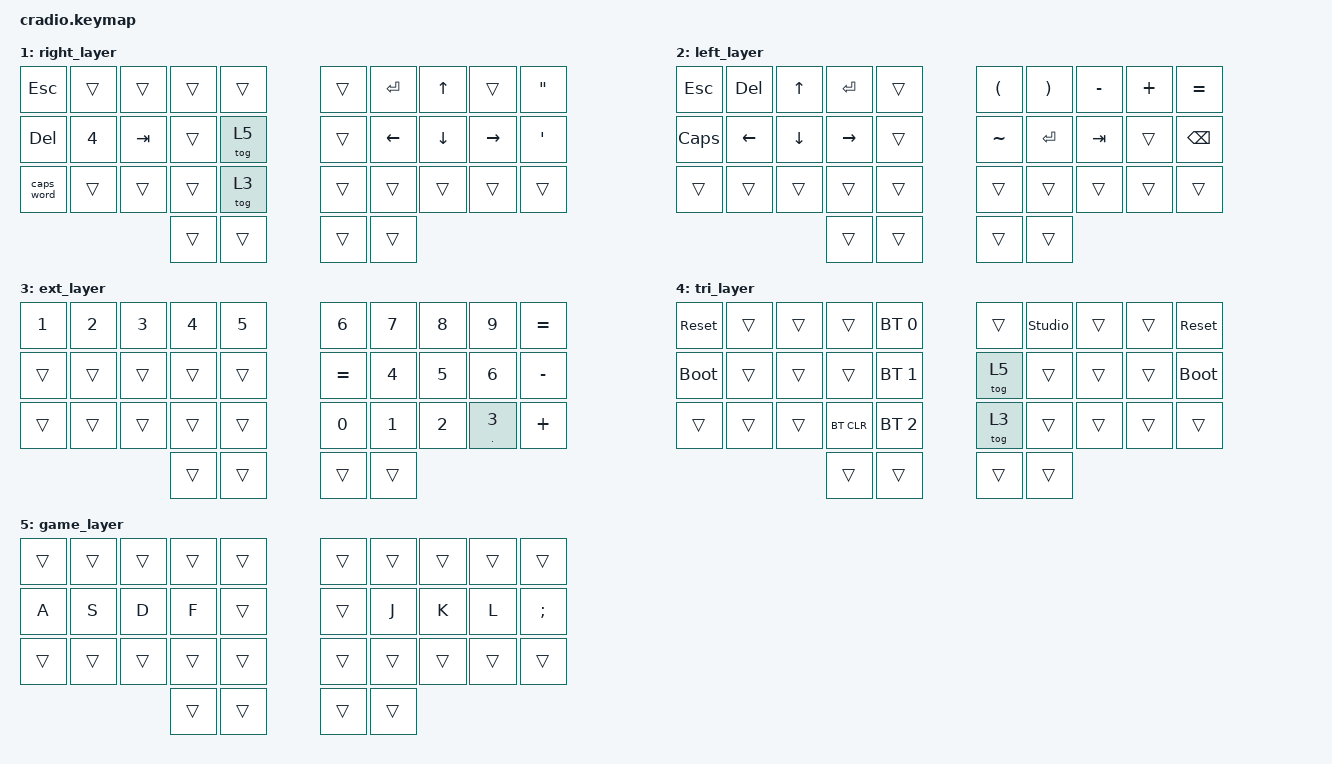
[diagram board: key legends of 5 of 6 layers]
// Copyright (c) 2022 The ZMK Contributors
// SPDX-License-Identifier: MIT

#include <behaviors.dtsi>
#include <dt-bindings/zmk/keys.h>
#include <dt-bindings/zmk/bt.h>

// Home row mods macro
#define HRML(k1,k2,k3,k4) &ht LSHFT k1  &ht LALT k2  &ht LCTRL k3  &ht LGUI k4
#define HRMR(k1,k2,k3,k4) &ht RGUI k1  &ht RCTRL k2  &ht RALT k3  &ht RSHFT k4

/ {
    behaviors {
        ht: hold_tap {
            compatible = "zmk,behavior-hold-tap";
            #binding-cells = <2>;
            flavor = "tap-preferred";
            tapping-term-ms = <220>;
            quick-tap-ms = <150>;
            require-prior-idle-ms = <100>;
            bindings = <&kp>, <&kp>;
        };

    };

    conditional_layers {
        compatible = "zmk,conditional-layers";
        tri_layer {
            if-layers = <1 2>;
            then-layer = <4>;
        };
    };

    keymap {
        compatible = "zmk,keymap";
        default_layer {
            bindings = <
        //╭──────────┬──────────┬──────────┬──────────┬──────────╮   ╭──────────┬──────────┬──────────┬──────────┬──────────╮
        //│  Q       │  W       │  E       │  R       │  T       │   │  Y       │  U       │  I       │  O       │  P       │
            &kp Q      &kp W      &kp E      &kp R      &kp T          &kp Y      &kp U      &kp I      &kp O      &kp P
        //├──────────┼──────────┼──────────┼──────────┼──────────┤   ├──────────┼──────────┼──────────┼──────────┼──────────┤
        //│  A       │  S       │  D       │  F       │  G       │   │  H       │  J       │  K       │  L       │ ; :      │
            HRML(A,        S,         D,         F)     &kp G          &kp H      HRMR(J,        K,         L,        SEMI)
        //├──────────┼──────────┼──────────┼──────────┼──────────┤   ├──────────┼──────────┼──────────┼──────────┼──────────┤
        //│  Z       │  X       │  C       │  V       │  B       │   │  N       │  M       │ , <      │ . >      │ / ?      │
            &kp Z      &kp X      &kp C      &kp V      &kp B          &kp N      &kp M      &kp COMMA  &kp DOT    &kp FSLH
        //╰──────────┴──────────┴──────────┼──────────┼──────────┤   ├──────────┼──────────┼──────────┴──────────┴──────────╯
                                           &lt 2 SPACE &lt 3 TAB       &lt 3 BSPC &lt 1 SPACE
        //                                 ╰──────────┴──────────╯   ╰──────────┴──────────╯
            >;
        };

        right_layer {
            bindings = <
        //╭──────────┬──────────┬──────────┬──────────┬──────────╮   ╭──────────┬──────────┬──────────┬──────────┬──────────╮
        //│   ESC    │          │          │          │          │   │          │    RET   │    UP    │          │     "    │
            &kp ESC    &trans     &trans     &trans     &trans         &trans     &kp RET    &kp UP     &trans     &kp DQT
        //├──────────┼──────────┼──────────┼──────────┼──────────┤   ├──────────┼──────────┼──────────┼──────────┼──────────┤
        //│ DELETE   │          │   TAB    │          │          │   │          │  LEFT    │   DOWN   │   RIGHT  │     '    │
            &kp DEL    &kp N4     &kp TAB     &trans     &tog 5        &trans     &kp LEFT   &kp DOWN   &kp RIGHT  &kp SQT
        //├──────────┼──────────┼──────────┼──────────┼──────────┤   ├──────────┼──────────┼──────────┼──────────┼──────────┤
        //│ CAPS     │          │          │          │          │   │          │          │          │          │          │
           &caps_word  &trans     &trans     &trans     &tog 3         &trans     &trans     &trans     &trans     &trans
        //╰──────────┴──────────┴──────────┼──────────┼──────────┤   ├──────────┼──────────┼──────────┴──────────┴──────────╯
                                             &trans     &trans         &trans     &trans
        //                                 ╰──────────┴──────────╯   ╰──────────┴──────────╯
            >;
        };

        left_layer {
            bindings = <
        //╭──────────┬──────────┬──────────┬──────────┬──────────╮   ╭──────────┬──────────┬──────────┬──────────┬──────────╮
        //│   ESC    │  DELETE  │    UP    │    RET   │          │   │    (     │     )    │    -     │    +     │     =    │
            &kp ESC    &kp DEL    &kp UP     &kp RET    &trans         &kp LPAR    &kp RPAR   &kp MINUS  &kp PLUS   &kp EQUAL
        //├──────────┼──────────┼──────────┼──────────┼──────────┤   ├──────────┼──────────┼──────────┼──────────┼──────────┤
        //│   CAPS   │   LEFT   │   DOWN   │   RIGHT  │          │   │    ~     │   RET    │    TAB   │          │   BSPC   │
            &kp CAPS   &kp LEFT   &kp DOWN   &kp RIGHT  &trans         &kp TILDE  &kp RET     &kp TAB    &trans     &kp BSPC
        //├──────────┼──────────┼──────────┼──────────┼──────────┤   ├──────────┼──────────┼──────────┼──────────┼──────────┤
        //│          │          │          │          │          │   │          │          │          │          │          │
            &trans     &trans     &trans     &trans     &trans         &trans     &trans      &trans     &trans     &trans
        //╰──────────┴──────────┴──────────┼──────────┼──────────┤   ├──────────┼──────────┼──────────┴──────────┴──────────╯
                                             &trans     &trans         &trans     &trans
        //                                 ╰──────────┴──────────╯   ╰──────────┴──────────╯
            >;
        };

        ext_layer {
            bindings = <
        //╭──────────┬──────────┬──────────┬──────────┬──────────╮   ╭──────────┬──────────┬──────────┬──────────┬──────────╮
        //│          │          │          │          │          │   │          │          │          │          │          │
            &kp N1     &kp N2     &kp N3     &kp N4     &kp N5         &kp N6     &kp N7     &kp N8     &kp N9     &kp EQUAL
        //├──────────┼──────────┼──────────┼──────────┼──────────┤   ├──────────┼──────────┼──────────┼──────────┼──────────┤
        //│          │          │          │          │          │   │          │          │          │          │          │
            &trans     &trans     &trans     &trans     &trans         &kp EQUAL  &kp N4     &kp N5     &kp N6     &kp MINUS
        //├──────────┼──────────┼──────────┼──────────┼──────────┤   ├──────────┼──────────┼──────────┼──────────┼──────────┤
        //│          │          │          │          │          │   │          │          │          │          │          │
            &trans     &trans     &trans     &trans     &trans         &kp N0     &kp N1     &kp N2     &ht DOT N3 &kp PLUS
        //╰──────────┴──────────┴──────────┼──────────┼──────────┤   ├──────────┼──────────┼──────────┴──────────┴──────────╯
                                             &trans     &trans         &trans     &trans
        //                                 ╰──────────┴──────────╯   ╰──────────┴──────────╯
            >;
        };

        tri_layer {
            bindings = <
        //╭──────────┬──────────┬──────────┬──────────┬──────────╮   ╭──────────┬──────────┬──────────┬──────────┬──────────╮
        //│ RESET    │          │          │          │PROFILE 0 │   │          │  UNLOCK  │          │          │  RESET   │
           &sys_reset  &trans     &trans     &trans    &bt BT_SEL 0    &trans &studio_unlock &trans     &trans    &sys_reset
        //├──────────┼──────────┼──────────┼──────────┼──────────┤   ├──────────┼──────────┼──────────┼──────────┼──────────┤
        //│BOOTLOADER│          │          │          │PROFILE 1 │   │          │          │          │          │BOOTLOADER│
          &bootloader  &trans     &trans     &trans    &bt BT_SEL 1    &tog 5     &trans     &trans     &trans    &bootloader
        //├──────────┼──────────┼──────────┼──────────┼──────────┤   ├──────────┼──────────┼──────────┼──────────┼──────────┤
        //│          │          │          │ CLEAR BT │PROFILE 2 │   │          │          │          │          │          │
            &trans     &trans     &trans    &bt BT_CLR &bt BT_SEL 2    &tog 3     &trans     &trans     &trans     &trans
        //╰──────────┴──────────┴──────────┼──────────┼──────────┤   ├──────────┼──────────┼──────────┴──────────┴──────────╯
                                             &trans     &trans         &trans     &trans
        //                                 ╰──────────┴──────────╯   ╰──────────┴──────────╯
            >;
        };

        game_layer {
            bindings = <
        //╭──────────┬──────────┬──────────┬──────────┬──────────╮   ╭──────────┬──────────┬──────────┬──────────┬──────────╮
        //│  Q       │  W       │  E       │  R       │  T       │   │  Y       │  U       │  I       │  O       │  P       │
            &trans     &trans     &trans     &trans     &trans         &trans     &trans      &trans     &trans     &trans
        //├──────────┼──────────┼──────────┼──────────┼──────────┤   ├──────────┼──────────┼──────────┼──────────┼──────────┤
        //│  A       │  S       │  D       │  F       │  G       │   │  H       │  J       │  K       │  L       │ ; :      │
            &kp A      &kp S      &kp D      &kp F      &trans         &trans     &kp J      &kp K      &kp L      &kp SEMI
        //├──────────┼──────────┼──────────┼──────────┼──────────┤   ├──────────┼──────────┼──────────┼──────────┼──────────┤
        //│  Z       │  X       │  C       │  V       │  B       │   │  N       │  M       │ , <      │ . >      │ / ?      │
            &trans     &trans     &trans     &trans     &trans         &trans     &trans      &trans     &trans     &trans
        //╰──────────┴──────────┴──────────┼──────────┼──────────┤   ├──────────┼──────────┼──────────┴──────────┴──────────╯
                                             &trans     &trans         &trans     &trans
        //                                 ╰──────────┴──────────╯   ╰──────────┴──────────╯
            >;
        };

    };
};
